# RL6842_IP_SVD register map
Vendor: Realtek
Registers are 32-bit, read-write, reset 0x0 unless marked. A register's access mark holds for its fields unless they carry their own. Offsets are from the block's base; [hi:lo] are bit positions; <NAME> marks a mode.

## THERMAL_REG
Base 0x4101D000
0x00 TM_GAIN reset 0x8284000 — Thermal Meter Gain Register
  [28:0] tm_a — This bit defines thermal meter gain. * Bit[28:14]: Integer part * Bit[13:0]: Decimal part
0x04 TM_OFFSET reset 0x371700 — Thermal Meter Offset Register
  [21:0] tm_b — This bit defines thermal meter offset. * Bit21: Signed bit * Bit[20:11]: Integer part * Bit[10:0]: Decimal part
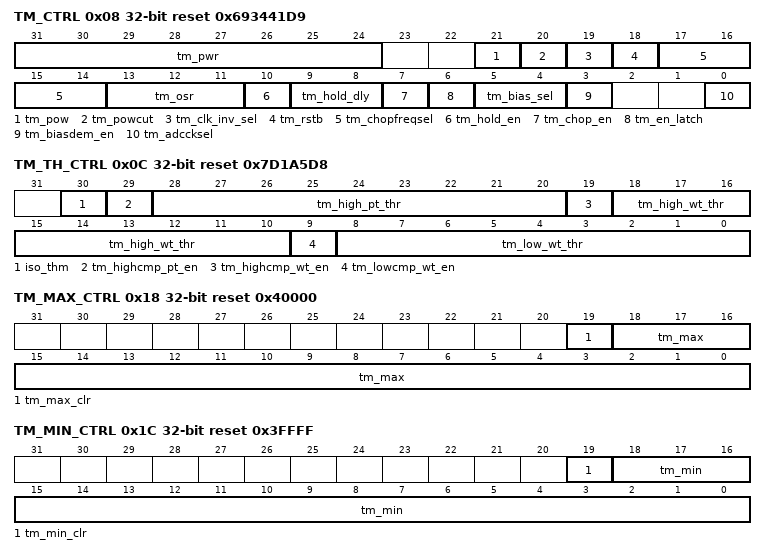
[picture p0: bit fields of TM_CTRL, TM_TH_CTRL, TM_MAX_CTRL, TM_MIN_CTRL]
0x08 TM_CTRL reset 0x693441D9 — Thermal Meter Control Register
  [31:24] tm_pwr — thm protect password. tm_pow,tm_powcut,tm_rstb,tm_highcmp_pt_en,tm_high_pt_thr, iso_thm can be programed only when this value is 8'h69.
  [21] tm_pow — thermal poweron signal * 0:power down * 1:power on
  [20] tm_powcut — Power cut * 0: disable power cut * 1: enable power cut
  [19] tm_clk_inv_sel — Clock phase invert select when read temperature. * 0: not invert (sample data in rising edge) * 1: invert (sample data in falling edge)
  [18] tm_rstb — Thermal reset signal. * 0: disable thermal * 1: enable thermal
  [17:14] tm_chopfreqsel — Chop frequecy select * 0: fs/64 * 1: fs/128 * 3: fs/256 * 7: fs/512 * 15: fs/1024
  [13:11] tm_osr — Deci filter DSR select * 0: 128 * 1: 256 * 2: 512 * 3: 1024
  [10] tm_hold_en — Hold output
  [9:8] tm_hold_dly — Hold delay, adjust TM_CLK_OUT width
  [7] tm_chop_en — Chop enable
  [6] tm_en_latch — Latch thermal sensor output immediately after power on for more accurate test
  [5:4] tm_bias_sel — Select ADC bias current * 0: 8uA * 1: 10uA * 2: 12uA * 3: 14uA
  [3] tm_biasdem_en — Bias DEM enable
  [0] tm_adccksel — Selelct ADC fs * 0: clk_src/256 * 1: clk_src/128
0x0C TM_TH_CTRL reset 0x7D1A5D8 — Thermal Meter Threshold Control Register
  [30] iso_thm — 1: ISO signals from thermal power domain 0: Release
  [29] tm_highcmp_pt_en — To enable compare tm_out with over temperature protect threshold: When tm_out[18:10] > tm_high_pt_thr, it will set aon reset. * 1: Enable the compare; * 0: Disable the compare.
  [28:20] tm_high_pt_thr — Set over temperature protection threshold for comparison with TEMP_OUT. Only between 0x046 (70centigrade) and 0x08C (140centigrade) are valid. * Bit28: Signed bit * Bit[27:20]: Integer part
  [19] tm_highcmp_wt_en — To enable compare tm_out with over temperature warning threshold: When tm_high_thr <= tm_out[18:10] < tm_high_pt_thr, it will set Interrupt pending flag ISR_TM_HIGH. * 1: Enable the compare; * 0: Disable the compare.
  [18:10] tm_high_wt_thr — Set the over temperature warning threshold for comparison with TEMP_OUT.Only values greater than 0 are supported * Bit18: Signed bit * Bit[17:10]: Integer part
  [9] tm_lowcmp_wt_en — To enable compare TM_OUT with set Low threshold: When tm_out[18:10] <= tm_low_thr, it will set Interrupt pending flag ISR_TM_LOW. * 1: Enable the compare * 0: Disable the compare
  [8:0] tm_low_wt_thr — Set the Low threshold for comparison with TEMP_OUT. * Bit8: Signed bit * Bit[7:0]: Integer part
0x10 TM_RESULT ro — Thermal Meter Temperature Result Register
  [18:0] tm_out — This bit defines real temperature. The result refreshes in real time. * Bit18: Signed bit * Bit[17:10]: Integer part * Bit[9:0]: Decimal part
0x14 TM_ADC_RESULT ro — Thermal Meter ADC Result Register
  [21:0] tm_adc_out — This bit defines thermal meter ADC output. The result refreshes in real time. * ADC output is a positive decimal number, real output=tm_out/2^22
0x18 TM_MAX_CTRL access per field reset 0x40000 — Thermal Meter Max Temperature Control Register
  [19] tm_max_clr wo — This bit defines clear max temperature * 0: not clear * 1: clear tm_max value
  [18:0] tm_max ro — These bits define max temperature.
0x1C TM_MIN_CTRL access per field reset 0x3FFFF — Thermal Meter Min Temperature Control Register
  [19] tm_min_clr wo — This bit defines clear min temperature * 0: not clear * 1: clear tm_min value
  [18:0] tm_min ro — These bits define min temperature.
0x20 TM_OUT_PWR_ON ro — Thermal Meter Power On Temperature Register
  [18:0] temp_out_poweron — This bit defines output temperature when power on reset. * Bit18: Signed bit * Bit[17:10]: Integer part * Bit[9:0]: Decimal part
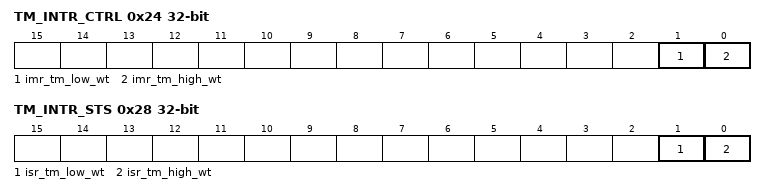
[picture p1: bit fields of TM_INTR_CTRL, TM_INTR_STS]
0x24 TM_INTR_CTRL — Thermal Meter Interrupt Control Register
  [1] imr_tm_low_wt — Interrupt control for thermal meter detect low temperature. * 0: Disable low temperature detect interrupt * 1: Enable low temperature detect interrupt
  [0] imr_tm_high_wt — Interrupt control for thermal meter detect over temperature warning. * 0: Disable over temperature warning detect interrupt * 1: Enable over temperature warning detect interrupt
0x28 TM_INTR_STS ro — Thermal Meter Interrupt Status Register
  [1] isr_tm_low_wt — Interrupt pending flag for thermal meter detect low temperature. * 0: normal * 1: interrupt pending
  [0] isr_tm_high_wt — Interrupt pending flag for thermal meter detect over temperature warning. * 0: normal * 1: interrupt pending
0x2C TM_TIMER reset 0xF — Thermal Meter Timer Register
  [7:0] time_period — Time period of auto power on
0x30 TM_DUMMY — Thermal Dummy Register
  [15:0] dummy — rsvd for hw
